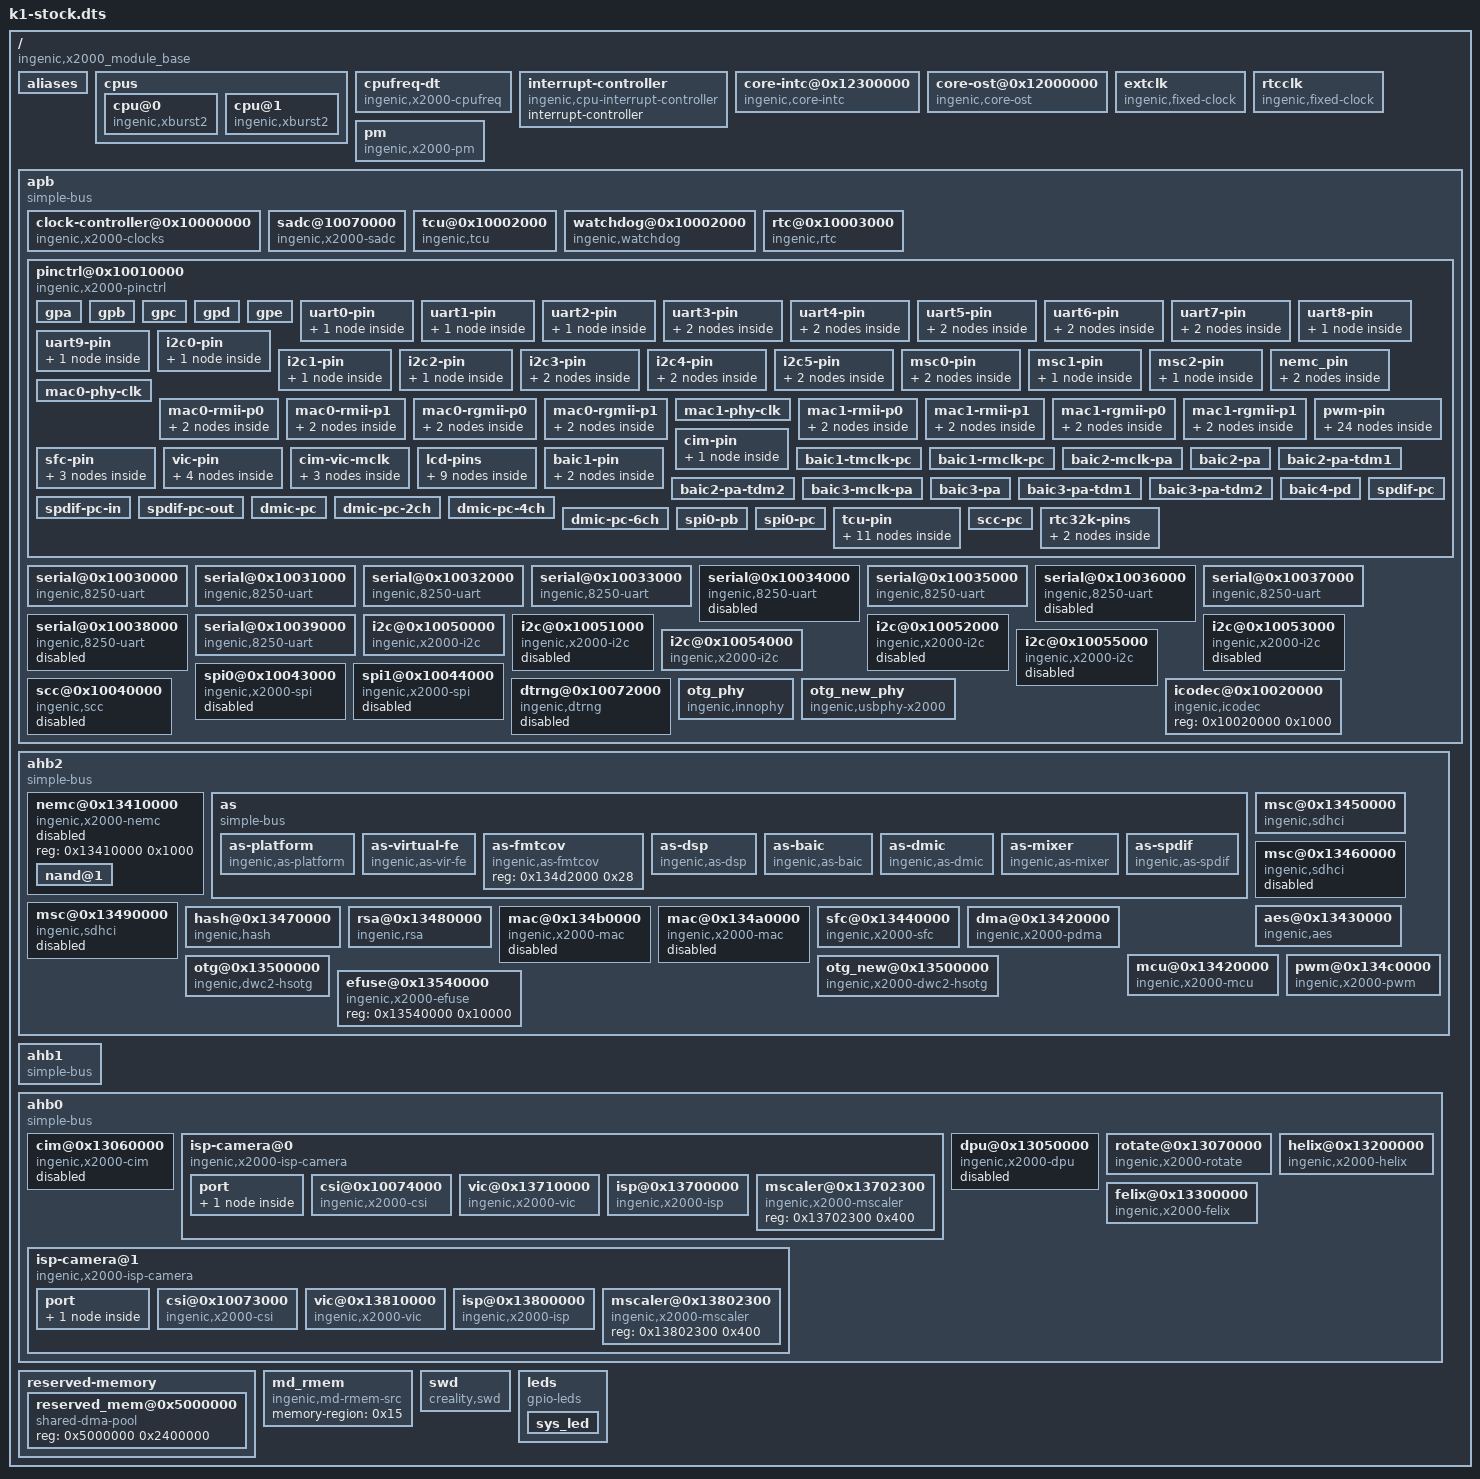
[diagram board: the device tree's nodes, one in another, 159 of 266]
/dts-v1/;

/ {
	#address-cells = <0x01>;
	#size-cells = <0x01>;
	compatible = "ingenic,x2000_module_base", "ingenic,x2000";

	aliases {
		i2c0 = "/apb/i2c@0x10050000";
		i2c1 = "/apb/i2c@0x10051000";
		i2c2 = "/apb/i2c@0x10052000";
		i2c3 = "/apb/i2c@0x10053000";
		i2c4 = "/apb/i2c@0x10054000";
		i2c5 = "/apb/i2c@0x10055000";
		uart0 = "/apb/serial@0x10030000";
		uart1 = "/apb/serial@0x10031000";
		uart2 = "/apb/serial@0x10032000";
		uart3 = "/apb/serial@0x10033000";
		uart4 = "/apb/serial@0x10034000";
		uart5 = "/apb/serial@0x10035000";
		uart6 = "/apb/serial@0x10036000";
		uart7 = "/apb/serial@0x10037000";
		uart8 = "/apb/serial@0x10038000";
		uart9 = "/apb/serial@0x10039000";
		mmc0 = "/ahb2/msc@0x13450000";
		mmc1 = "/ahb2/msc@0x13460000";
		mmc2 = "/ahb2/msc@0x13490000";
		mac0 = "/ahb2/mac@0x134b0000";
		mac1 = "/ahb2/mac@0x134a0000";
		spi0 = "/apb/spi0@0x10043000";
		spi1 = "/apb/spi1@0x10044000";
		pwm = "/ahb2/pwm@0x134c0000";
	};

	cpus {
		#address-cells = <0x01>;
		#size-cells = <0x00>;

		cpu@0 {
			device_type = "cpu";
			compatible = "ingenic,xburst2";
			reg = <0x00>;
			clock-frequency = <0x2faf0800>;
		};

		cpu@1 {
			device_type = "cpu";
			compatible = "ingenic,xburst2";
			reg = <0x01>;
			clock-frequency = <0x2faf0800>;
		};
	};

	cpufreq-dt {
		compatible = "ingenic,x2000-cpufreq";
		status = "okay";
		operating-points = <0x124f80 0xdbba0 0xb71b0 0xdbba0 0x927c0 0xdbba0 0x7a120 0xdbba0 0x61a80 0xdbba0 0x5b8d8 0xdbba0 0x493e0 0xdbba0 0x30d40 0xdbba0>;
	};

	interrupt-controller {
		#address-cells = <0x00>;
		#interrupt-cells = <0x01>;
		interrupt-controller;
		compatible = "ingenic,cpu-interrupt-controller";
		linux,phandle = <0x01>;
		phandle = <0x01>;
	};

	core-intc@0x12300000 {
		compatible = "ingenic,core-intc";
		reg = <0x12300000 0x1000 0x10001000 0x1000>;
		interrupt-controller;
		#interrupt-cells = <0x01>;
		cpu-intc-map = <0x00 0x00 0x01 0x100 0x02 0x200 0x03 0x300>;
		interrupt-parent = <0x01>;
		interrupts = <0x02>;
		interrupt-names = "intc";
		linux,phandle = <0x04>;
		phandle = <0x04>;
	};

	core-ost@0x12000000 {
		compatible = "ingenic,core-ost";
		reg = <0x12000000 0x10000 0x12100000 0x10000>;
		interrupt-parent = <0x01>;
		interrupt-names = "sys_ost";
		interrupts = <0x04>;
		cpu-ost-map = <0x00 0x00 0x01 0x100>;
	};

	extclk {
		compatible = "ingenic,fixed-clock";
		clock-output-names = "ext";
		#clock-cells = <0x00>;
		clock-frequency = <0x16e3600>;
		linux,phandle = <0x02>;
		phandle = <0x02>;
	};

	rtcclk {
		compatible = "ingenic,fixed-clock";
		clock-output-names = "rtc_ext";
		#clock-cells = <0x00>;
		clock-frequency = <0x8000>;
		linux,phandle = <0x03>;
		phandle = <0x03>;
	};

	pm {
		compatible = "ingenic,x2000-pm";
		status = "okay";
	};

	apb {
		compatible = "simple-bus";
		#address-cells = <0x01>;
		#size-cells = <0x01>;
		ranges;

		clock-controller@0x10000000 {
			compatible = "ingenic,x2000-clocks";
			reg = <0x10000000 0x100>;
			clocks = <0x02 0x03>;
			clock-names = "ext", "rtc_ext";
			#clock-cells = <0x01>;
			little-endian;
			linux,phandle = <0x05>;
			phandle = <0x05>;
		};

		sadc@10070000 {
			compatible = "ingenic,x2000-sadc";
			reg = <0x10070000 0x32>;
			interrupt-parent = <0x04>;
			interrupts = <0x0b>;
			interrupt-controller;
			status = "ok";
		};

		tcu@0x10002000 {
			compatible = "ingenic,tcu";
			reg = <0x10002000 0x1000>;
			interrupt-parent = <0x04>;
			interrupt-names = "default";
			interrupts = <0x1b>;
			clocks = <0x05 0x49>;
			clock-names = "gate_tcu";
			status = "ok";
		};

		watchdog@0x10002000 {
			compatible = "ingenic,watchdog";
			reg = <0x10002000 0x40>;
			interrupt-parent = <0x04>;
			interrupts = <0x1b>;
			status = "ok";
		};

		rtc@0x10003000 {
			compatible = "ingenic,rtc";
			reg = <0x10003000 0x4c>;
			interrupt-parent = <0x04>;
			interrupts = <0x20>;
			system-power-controller;
			power-on-press-ms = <0x3e8>;
			status = "ok";
		};

		pinctrl@0x10010000 {
			compatible = "ingenic,x2000-pinctrl";
			reg = <0x10010000 0x1000>;
			ingenic,num-chips = <0x05>;
			ingenic,regs-offset = <0x100>;
			ingenic,gpa_voltage = <0x02>;
			ingenic,gpe_msc_voltage = <0x01>;

			gpa {
				gpio-controller;
				#gpio-cells = <0x03>;
				#ingenic,pincfg-cells = <0x03>;
				#ingenic,pinmux-cells = <0x02>;
				interrupts = <0x11>;
				interrupt-parent = <0x04>;
				interrupt-controller;
				#interrupt-cells = <0x03>;
				ingenic,num-gpios = <0x20>;
				linux,phandle = <0x08>;
				phandle = <0x08>;
			};

			gpb {
				gpio-controller;
				#gpio-cells = <0x03>;
				#ingenic,pincfg-cells = <0x03>;
				#ingenic,pinmux-cells = <0x02>;
				interrupts = <0x10>;
				interrupt-parent = <0x04>;
				interrupt-controller;
				#interrupt-cells = <0x03>;
				ingenic,num-gpios = <0x20>;
				linux,phandle = <0x09>;
				phandle = <0x09>;
			};

			gpc {
				gpio-controller;
				#gpio-cells = <0x03>;
				#ingenic,pincfg-cells = <0x03>;
				#ingenic,pinmux-cells = <0x02>;
				interrupts = <0x0f>;
				interrupt-parent = <0x04>;
				interrupt-controller;
				#interrupt-cells = <0x03>;
				ingenic,num-gpios = <0x20>;
				linux,phandle = <0x07>;
				phandle = <0x07>;
			};

			gpd {
				gpio-controller;
				#gpio-cells = <0x03>;
				#ingenic,pincfg-cells = <0x03>;
				#ingenic,pinmux-cells = <0x02>;
				interrupts = <0x0e>;
				interrupt-parent = <0x04>;
				interrupt-controller;
				#interrupt-cells = <0x03>;
				ingenic,num-gpios = <0x20>;
				linux,phandle = <0x06>;
				phandle = <0x06>;
			};

			gpe {
				gpio-controller;
				#gpio-cells = <0x03>;
				#ingenic,pincfg-cells = <0x03>;
				#ingenic,pinmux-cells = <0x02>;
				interrupts = <0x0d>;
				interrupt-parent = <0x04>;
				interrupt-controller;
				#interrupt-cells = <0x03>;
				ingenic,num-gpios = <0x20>;
				linux,phandle = <0x0a>;
				phandle = <0x0a>;
			};

			uart0-pin {

				uart0-pd {
					ingenic,pinmux = <0x06 0x17 0x1a>;
					ingenic,pinmux-funcsel = <0x02>;
				};
			};

			uart1-pin {

				uart1-pc {
					ingenic,pinmux = <0x07 0x17 0x18>;
					ingenic,pinmux-funcsel = <0x01>;
					linux,phandle = <0x0b>;
					phandle = <0x0b>;
				};
			};

			uart2-pin {

				uart2-pd {
					ingenic,pinmux = <0x06 0x1e 0x1f>;
					ingenic,pinmux-funcsel = <0x00>;
					linux,phandle = <0x0c>;
					phandle = <0x0c>;
				};
			};

			uart3-pin {

				uart3-pc {
					ingenic,pinmux = <0x07 0x19 0x1a>;
					ingenic,pinmux-funcsel = <0x00>;
				};

				uart3-pd {
					ingenic,pinmux = <0x06 0x00 0x03>;
					ingenic,pinmux-funcsel = <0x01>;
					linux,phandle = <0x0d>;
					phandle = <0x0d>;
				};
			};

			uart4-pin {

				uart4-pa {
					ingenic,pinmux = <0x08 0x00 0x03>;
					ingenic,pinmux-funcsel = <0x01>;
				};

				uart4-pc {
					ingenic,pinmux = <0x07 0x09 0x0c>;
					ingenic,pinmux-funcsel = <0x03>;
				};
			};

			uart5-pin {

				uart5-pa {
					ingenic,pinmux = <0x08 0x04 0x05>;
					ingenic,pinmux-funcsel = <0x01>;
					linux,phandle = <0x0e>;
					phandle = <0x0e>;
				};

				uart5-pc {
					ingenic,pinmux = <0x07 0x05 0x06>;
					ingenic,pinmux-funcsel = <0x03>;
				};
			};

			uart6-pin {

				uart6-pa {
					ingenic,pinmux = <0x08 0x06 0x07>;
					ingenic,pinmux-funcsel = <0x01>;
				};

				uart6-pc {
					ingenic,pinmux = <0x07 0x07 0x08>;
					ingenic,pinmux-funcsel = <0x03>;
				};
			};

			uart7-pin {

				uart7-pa {
					ingenic,pinmux = <0x08 0x08 0x09>;
					ingenic,pinmux-funcsel = <0x01>;
					linux,phandle = <0x0f>;
					phandle = <0x0f>;
				};

				uart7-pc {
					ingenic,pinmux = <0x07 0x01 0x02>;
					ingenic,pinmux-funcsel = <0x03>;
				};
			};

			uart8-pin {

				uart8-pb {
					ingenic,pinmux = <0x09 0x1c 0x1d>;
					ingenic,pinmux-funcsel = <0x03>;
				};
			};

			uart9-pin {

				uart9-pb {
					ingenic,pinmux = <0x09 0x1e 0x1f>;
					ingenic,pinmux-funcsel = <0x03>;
					linux,phandle = <0x10>;
					phandle = <0x10>;
				};
			};

			i2c0-pin {

				i2c0-pc {
					ingenic,pinmux = <0x07 0x0d 0x0e>;
					ingenic,pinmux-funcsel = <0x03>;
				};
			};

			i2c1-pin {

				i2c1-pc {
					ingenic,pinmux = <0x07 0x17 0x18>;
					ingenic,pinmux-funcsel = <0x02>;
				};
			};

			i2c2-pin {

				i2c2-pb {
					ingenic,pinmux = <0x09 0x16 0x17>;
					ingenic,pinmux-funcsel = <0x02>;
				};
			};

			i2c3-pin {

				i2c3-pd {
					ingenic,pinmux = <0x06 0x1e 0x1f>;
					ingenic,pinmux-funcsel = <0x01>;
				};

				i2c3-pa {
					ingenic,pinmux = <0x08 0x10 0x11>;
					ingenic,pinmux-funcsel = <0x00>;
				};
			};

			i2c4-pin {

				i2c4-pc {
					ingenic,pinmux = <0x07 0x19 0x1a>;
					ingenic,pinmux-funcsel = <0x01>;
				};

				i2c4-pd {
					ingenic,pinmux = <0x06 0x00 0x01>;
					ingenic,pinmux-funcsel = <0x02>;
				};
			};

			i2c5-pin {

				i2c5-pc {
					ingenic,pinmux = <0x07 0x1b 0x1c>;
					ingenic,pinmux-funcsel = <0x01>;
				};

				i2c5-pd {
					ingenic,pinmux = <0x06 0x04 0x05>;
					ingenic,pinmux-funcsel = <0x01>;
				};
			};

			msc0-pin {

				msc0-4bit {
					ingenic,pinmux = <0x06 0x11 0x16>;
					ingenic,pinmux-funcsel = <0x00>;
				};

				msc0-8bit {
					ingenic,pinmux = <0x06 0x11 0x1a>;
					ingenic,pinmux-funcsel = <0x00>;
					linux,phandle = <0x12>;
					phandle = <0x12>;
				};
			};

			msc1-pin {

				msc1-4bit {
					ingenic,pinmux = <0x06 0x08 0x0d>;
					ingenic,pinmux-funcsel = <0x00>;
				};
			};

			msc2-pin {

				msc2-4bit {
					ingenic,pinmux = <0x0a 0x00 0x05>;
					ingenic,pinmux-funcsel = <0x00>;
				};
			};

			nemc_pin {

				nemc_pb {
					ingenic,pinmux = <0x09 0x00 0x1f>;
					ingenic,pinmux-funcsel = <0x00>;
				};

				nemc_pc {
					ingenic,pinmux = <0x07 0x17 0x18>;
					ingenic,pinmux-funcsel = <0x03>;
				};
			};

			mac0-phy-clk {
				ingenic,pinmux = <0x07 0x01 0x01>;
				ingenic,pinmux-funcsel = <0x01>;
				ingenic,pincfg = <0x07 0x01 0x01 0x40009>;
			};

			mac0-rmii-p0 {

				mac0-rmii-normal {
					ingenic,pinmux = <0x07 0x06 0x07 0x07 0x0b 0x0b 0x07 0x0f 0x0f>;
					ingenic,pinmux-funcsel = <0x01>;
					ingenic,pincfg = <0x07 0x06 0x07 0x1000b 0x07 0x0b 0x0b 0x1000b 0x07 0x0f 0x0f 0x1000b>;
				};

				mac0-rmii-p0-rst {
					ingenic,pinmux = <0x07 0x06 0x07 0x07 0x0b 0x0b 0x07 0x0f 0x0f>;
					ingenic,pinmux-funcsel = <0x06>;
					ingenic,pincfg = <0x07 0x06 0x07 0x10002 0x07 0x0b 0x0b 0x10002 0x07 0x0f 0x0f 0x10002>;
				};
			};

			mac0-rmii-p1 {

				mac0-rmii-p1-normal {
					ingenic,pinmux = <0x07 0x02 0x03 0x07 0x0a 0x0a 0x07 0x0c 0x0d>;
					ingenic,pinmux-funcsel = <0x01>;
					ingenic,pincfg = <0x07 0x02 0x03 0x40009 0x07 0x0a 0x0a 0x40009 0x07 0x0c 0x0d 0x40009>;
				};

				mac0-rmii-p1-nomdio {
					ingenic,pinmux = <0x07 0x02 0x03 0x07 0x0a 0x0a>;
					ingenic,pinmux-funcsel = <0x01>;
					ingenic,pincfg = <0x07 0x02 0x03 0x40009 0x07 0x0a 0x0a 0x40009>;
				};
			};

			mac0-rgmii-p0 {

				mac0-rgmii-normal {
					ingenic,pinmux = <0x07 0x06 0x09 0x07 0x0b 0x0b 0x07 0x0f 0x0f>;
					ingenic,pinmux-funcsel = <0x01>;
					ingenic,pincfg = <0x07 0x06 0x09 0x1000b 0x07 0x0b 0x0b 0x1000b 0x07 0x0f 0x0f 0x1000b>;
				};

				mac0-rgmii-p0-rst {
					ingenic,pinmux = <0x07 0x06 0x09 0x07 0x0b 0x0b 0x07 0x0f 0x0f>;
					ingenic,pinmux-funcsel = <0x06>;
					ingenic,pincfg = <0x07 0x06 0x09 0x10002 0x07 0x0b 0x0b 0x10002 0x07 0x0f 0x0f 0x10002>;
				};
			};

			mac0-rgmii-p1 {

				mac0-rgmii-p1-normal {
					ingenic,pinmux = <0x07 0x02 0x05 0x07 0x0a 0x0a 0x07 0x0c 0x0e>;
					ingenic,pinmux-funcsel = <0x01>;
					ingenic,pincfg = <0x07 0x02 0x05 0x40009 0x07 0x0a 0x0a 0x40009 0x07 0x0c 0x0e 0x40009>;
				};

				mac0-rgmii-p1-nomdio {
					ingenic,pinmux = <0x07 0x02 0x05 0x07 0x0a 0x0a 0x07 0x0e 0x0e>;
					ingenic,pinmux-funcsel = <0x01>;
					ingenic,pincfg = <0x07 0x02 0x05 0x40009 0x07 0x0a 0x0a 0x40009 0x07 0x0e 0x0e 0x40009>;
				};
			};

			mac1-phy-clk {
				ingenic,pinmux = <0x09 0x17 0x17>;
				ingenic,pinmux-funcsel = <0x03>;
				ingenic,pincfg = <0x07 0x17 0x17 0x40009>;
			};

			mac1-rmii-p0 {

				mac1-rmii-normal {
					ingenic,pinmux = <0x09 0x0c 0x0d 0x09 0x12 0x12 0x09 0x16 0x16>;
					ingenic,pinmux-funcsel = <0x03>;
					ingenic,pincfg = <0x09 0x0c 0x0d 0x1000b 0x09 0x12 0x12 0x1000b 0x09 0x16 0x16 0x1000b>;
				};

				mac1-rmii-p0-rst {
					ingenic,pinmux = <0x09 0x0c 0x0d 0x09 0x12 0x12 0x09 0x16 0x16>;
					ingenic,pinmux-funcsel = <0x06>;
					ingenic,pincfg = <0x09 0x0c 0x0d 0x10002 0x09 0x12 0x12 0x10002 0x09 0x16 0x16 0x10002>;
				};
			};

			mac1-rmii-p1 {

				mac1-rmii-p1-normal {
					ingenic,pinmux = <0x09 0x08 0x09 0x09 0x11 0x11 0x09 0x13 0x14>;
					ingenic,pinmux-funcsel = <0x03>;
					ingenic,pincfg = <0x09 0x08 0x09 0x40009 0x09 0x11 0x11 0x40009 0x09 0x13 0x14 0x40009>;
				};

				mac1-rmii-p1-nomdio {
					ingenic,pinmux = <0x09 0x08 0x09 0x09 0x11 0x11>;
					ingenic,pinmux-funcsel = <0x03>;
					ingenic,pincfg = <0x09 0x08 0x09 0x40009 0x09 0x11 0x11 0x40009>;
				};
			};

			mac1-rgmii-p0 {

				mac1-rgmii-normal {
					ingenic,pinmux = <0x09 0x0c 0x0f 0x09 0x12 0x12 0x09 0x16 0x16>;
					ingenic,pinmux-funcsel = <0x03>;
					ingenic,pincfg = <0x09 0x0c 0x0f 0x1000b 0x09 0x12 0x12 0x1000b 0x09 0x16 0x16 0x1000b>;
				};

				mac1-rgmii-p0-rst {
					ingenic,pinmux = <0x09 0x0c 0x0f 0x09 0x12 0x12 0x09 0x16 0x16>;
					ingenic,pinmux-funcsel = <0x06>;
					ingenic,pincfg = <0x09 0x0c 0x0f 0x10002 0x09 0x12 0x12 0x10002 0x09 0x16 0x16 0x10002>;
				};
			};

			mac1-rgmii-p1 {

				mac1-rgmii-p1-normal {
					ingenic,pinmux = <0x09 0x08 0x0b 0x09 0x11 0x11 0x09 0x13 0x15>;
					ingenic,pinmux-funcsel = <0x03>;
					ingenic,pincfg = <0x09 0x08 0x0b 0x40009 0x09 0x11 0x11 0x40009 0x09 0x13 0x15 0x40009>;
				};

				mac1-rgmii-p1-nomdio {
					ingenic,pinmux = <0x09 0x08 0x0b 0x09 0x11 0x11 0x09 0x15 0x15>;
					ingenic,pinmux-funcsel = <0x03>;
					ingenic,pincfg = <0x09 0x08 0x0b 0x40009 0x09 0x11 0x11 0x40009 0x09 0x15 0x15 0x40009>;
				};
			};

			pwm-pin {

				pwm0_pc {
					ingenic,pinmux = <0x07 0x00 0x00>;
					ingenic,pinmux-funcsel = <0x00>;
				};

				pwm1_pc {
					ingenic,pinmux = <0x07 0x01 0x01>;
					ingenic,pinmux-funcsel = <0x00>;
				};

				pwm2_pc {
					ingenic,pinmux = <0x07 0x02 0x02>;
					ingenic,pinmux-funcsel = <0x00>;
				};

				pwm3_pc {
					ingenic,pinmux = <0x07 0x03 0x03>;
					ingenic,pinmux-funcsel = <0x00>;
				};

				pwm4_pc {
					ingenic,pinmux = <0x07 0x04 0x04>;
					ingenic,pinmux-funcsel = <0x00>;
				};

				pwm5_pc {
					ingenic,pinmux = <0x07 0x05 0x05>;
					ingenic,pinmux-funcsel = <0x00>;
				};

				pwm6_pc {
					ingenic,pinmux = <0x07 0x06 0x06>;
					ingenic,pinmux-funcsel = <0x00>;
				};

				pwm7_pc {
					ingenic,pinmux = <0x07 0x07 0x07>;
					ingenic,pinmux-funcsel = <0x00>;
				};

				pwm8_pc {
					ingenic,pinmux = <0x07 0x08 0x08>;
					ingenic,pinmux-funcsel = <0x00>;
				};

				pwm9_pc {
					ingenic,pinmux = <0x07 0x09 0x09>;
					ingenic,pinmux-funcsel = <0x00>;
				};

				pwm10_pc {
					ingenic,pinmux = <0x07 0x0a 0x0a>;
					ingenic,pinmux-funcsel = <0x00>;
				};

				pwm11_pc {
					ingenic,pinmux = <0x07 0x0b 0x0b>;
					ingenic,pinmux-funcsel = <0x00>;
				};

				pwm12_pc {
					ingenic,pinmux = <0x07 0x0c 0x0c>;
					ingenic,pinmux-funcsel = <0x00>;
				};

				pwm13_pc {
					ingenic,pinmux = <0x07 0x0d 0x0d>;
					ingenic,pinmux-funcsel = <0x00>;
				};

				pwm14_pc {
					ingenic,pinmux = <0x07 0x0e 0x0e>;
					ingenic,pinmux-funcsel = <0x00>;
				};

				pwm15_pc {
					ingenic,pinmux = <0x07 0x0f 0x0f>;
					ingenic,pinmux-funcsel = <0x00>;
				};

				pwm0_pd {
					ingenic,pinmux = <0x06 0x1e 0x1e>;
					ingenic,pinmux-funcsel = <0x02>;
				};

				pwm1_pd {
					ingenic,pinmux = <0x06 0x1f 0x1f>;
					ingenic,pinmux-funcsel = <0x02>;
				};

				pwm2_pe {
					ingenic,pinmux = <0x0a 0x00 0x00>;
					ingenic,pinmux-funcsel = <0x01>;
				};

				pwm3_pe {
					ingenic,pinmux = <0x0a 0x01 0x01>;
					ingenic,pinmux-funcsel = <0x01>;
				};

				pwm4_pe {
					ingenic,pinmux = <0x0a 0x02 0x02>;
					ingenic,pinmux-funcsel = <0x01>;
				};

				pwm5_pe {
					ingenic,pinmux = <0x0a 0x03 0x03>;
					ingenic,pinmux-funcsel = <0x01>;
				};

				pwm6_pe {
					ingenic,pinmux = <0x0a 0x04 0x04>;
					ingenic,pinmux-funcsel = <0x01>;
				};

				pwm7_pe {
					ingenic,pinmux = <0x0a 0x05 0x05>;
					ingenic,pinmux-funcsel = <0x01>;
				};
			};

			sfc-pin {

				sfc-pd_8bit {
					ingenic,pinmux = <0x06 0x11 0x1a>;
					ingenic,pinmux-funcsel = <0x01>;
				};

				sfc-pd_4bit {
					ingenic,pinmux = <0x06 0x11 0x16>;
					ingenic,pinmux-funcsel = <0x01>;
				};

				sfc-pe {
					ingenic,pinmux = <0x0a 0x10 0x15>;
					ingenic,pinmux-funcsel = <0x00>;
				};
			};

			cim-pin {

				cim-pa {
					ingenic,pinmux = <0x08 0x00 0x07 0x08 0x0c 0x0f>;
					ingenic,pinmux-funcsel = <0x00>;
				};
			};

			vic-pin {

				vic-pa-low-8bit {
					ingenic,pinmux = <0x08 0x00 0x07 0x08 0x0c 0x0e>;
					ingenic,pinmux-funcsel = <0x00>;
				};

				vic-pa-low-10bit {
					ingenic,pinmux = <0x08 0x00 0x09 0x08 0x0c 0x0e>;
					ingenic,pinmux-funcsel = <0x00>;
				};

				vic-pa-high-10bit {
					ingenic,pinmux = <0x08 0x02 0x0e>;
					ingenic,pinmux-funcsel = <0x00>;
				};

				vic-pa-12bit {
					ingenic,pinmux = <0x08 0x00 0x0e>;
					ingenic,pinmux-funcsel = <0x00>;
				};
			};

			cim-vic-mclk {

				cim-vic-mclk-pe-24M {
					ingenic,pinmux = <0x0a 0x18 0x18>;
					ingenic,pinmux-funcsel = <0x00>;
				};

				cim-vic-mclk-pe {
					ingenic,pinmux = <0x0a 0x18 0x18>;
					ingenic,pinmux-funcsel = <0x01>;
				};

				cim-vic-mclk-pc {
					ingenic,pinmux = <0x07 0x0f 0x0f>;
					ingenic,pinmux-funcsel = <0x02>;
				};
			};

			lcd-pins {

				tft-lcd-pb-rgb888 {
					ingenic,pinmux = <0x09 0x00 0x1b>;
					ingenic,pinmux-funcsel = <0x01>;
				};

				tft-lcd-pb-rgb888_to_18bit {
					ingenic,pinmux = <0x09 0x02 0x07 0x09 0x0a 0x0f 0x09 0x12 0x1b>;
					ingenic,pinmux-funcsel = <0x01>;
				};

				tft-lcd-pb-rgb565 {
					ingenic,pinmux = <0x09 0x00 0x0f 0x09 0x18 0x1b>;
					ingenic,pinmux-funcsel = <0x01>;
				};

				tft-lcd-pb-rgb666 {
					ingenic,pinmux = <0x09 0x00 0x11 0x09 0x18 0x1b>;
					ingenic,pinmux-funcsel = <0x01>;
				};

				smart-lcd-pb-16bit {
					ingenic,pinmux = <0x09 0x00 0x0f 0x09 0x19 0x1b>;
					ingenic,pinmux-funcsel = <0x02>;
				};

				smart-lcd-pb-9bit {
					ingenic,pinmux = <0x09 0x00 0x08 0x09 0x19 0x1b>;
					ingenic,pinmux-funcsel = <0x02>;
				};

				smart-lcd-pb-8bit {
					ingenic,pinmux = <0x09 0x00 0x07 0x09 0x19 0x1b>;
					ingenic,pinmux-funcsel = <0x02>;
				};

				smart-lcd-pb-spi {
					ingenic,pinmux = <0x09 0x00 0x00 0x09 0x19 0x1a>;
					ingenic,pinmux-funcsel = <0x02>;
				};

				smart-lcd-pb-te {
					ingenic,pinmux = <0x09 0x1b 0x1b>;
					ingenic,pinmux-funcsel = <0x02>;
				};
			};

			baic1-tmclk-pc {
				ingenic,pinmux = <0x07 0x08 0x08>;
				ingenic,pinmux-funcsel = <0x02>;
			};

			baic1-rmclk-pc {
				ingenic,pinmux = <0x07 0x01 0x01>;
				ingenic,pinmux-funcsel = <0x02>;
			};

			baic1-pin {

				baic1-pin-pc {
					ingenic,pinmux = <0x07 0x02 0x07>;
					ingenic,pinmux-funcsel = <0x02>;
				};

				baic1-cpin-pc {
					ingenic,pinmux = <0x07 0x04 0x07>;
					ingenic,pinmux-funcsel = <0x02>;
				};
			};

			baic2-mclk-pa {
				ingenic,pinmux = <0x08 0x07 0x07>;
				ingenic,pinmux-funcsel = <0x02>;
			};

			baic2-pa {
				ingenic,pinmux = <0x08 0x09 0x0d 0x08 0x11 0x11>;
				ingenic,pinmux-funcsel = <0x02>;
			};

			baic2-pa-tdm1 {
				ingenic,pinmux = <0x08 0x09 0x0a 0x08 0x11 0x11>;
				ingenic,pinmux-funcsel = <0x02>;
			};

			baic2-pa-tdm2 {
				ingenic,pinmux = <0x08 0x09 0x0b 0x08 0x11 0x11>;
				ingenic,pinmux-funcsel = <0x02>;
			};

			baic3-mclk-pa {
				ingenic,pinmux = <0x08 0x00 0x00>;
				ingenic,pinmux-funcsel = <0x02>;
			};

			baic3-pa {
				ingenic,pinmux = <0x08 0x02 0x06 0x08 0x10 0x10>;
				ingenic,pinmux-funcsel = <0x02>;
			};

			baic3-pa-tdm1 {
				ingenic,pinmux = <0x08 0x02 0x03 0x08 0x10 0x10>;
				ingenic,pinmux-funcsel = <0x02>;
			};

			baic3-pa-tdm2 {
				ingenic,pinmux = <0x08 0x02 0x04 0x08 0x10 0x10>;
				ingenic,pinmux-funcsel = <0x02>;
			};

			baic4-pd {
				ingenic,pinmux = <0x06 0x02 0x05>;
				ingenic,pinmux-funcsel = <0x02>;
				ingenic,pincfg = <0x06 0x04 0x04 0x10002>;
			};

			spdif-pc {
				ingenic,pinmux = <0x07 0x0d 0x0e>;
				ingenic,pinmux-funcsel = <0x02>;
				ingenic,pincfg = <0x07 0x0e 0x0e 0x70009>;
			};

			spdif-pc-in {
				ingenic,pinmux = <0x07 0x0d 0x0d>;
				ingenic,pinmux-funcsel = <0x02>;
			};

			spdif-pc-out {
				ingenic,pinmux = <0x07 0x0e 0x0e>;
				ingenic,pinmux-funcsel = <0x02>;
				ingenic,pincfg = <0x07 0x0e 0x0e 0x70009>;
			};

			dmic-pc {
				ingenic,pinmux = <0x07 0x14 0x18>;
				ingenic,pinmux-funcsel = <0x00>;
			};

			dmic-pc-2ch {
				ingenic,pinmux = <0x07 0x14 0x15>;
				ingenic,pinmux-funcsel = <0x00>;
			};

			dmic-pc-4ch {
				ingenic,pinmux = <0x07 0x14 0x16>;
				ingenic,pinmux-funcsel = <0x00>;
			};

			dmic-pc-6ch {
				ingenic,pinmux = <0x07 0x14 0x17>;
				ingenic,pinmux-funcsel = <0x00>;
			};

			spi0-pb {
				ingenic,pinmux = <0x09 0x1c 0x1f>;
				ingenic,pinmux-funcsel = <0x01>;
			};

			spi0-pc {
				ingenic,pinmux = <0x07 0x09 0x0c>;
				ingenic,pinmux-funcsel = <0x02>;
			};

			tcu-pin {

				tcu0_pc {
					ingenic,pinmux = <0x07 0x00 0x01>;
					ingenic,pinmux-funcsel = <0x00>;
				};

				tcu1_pc {
					ingenic,pinmux = <0x07 0x02 0x03>;
					ingenic,pinmux-funcsel = <0x00>;
				};

				tcu2_pc {
					ingenic,pinmux = <0x07 0x04 0x05>;
					ingenic,pinmux-funcsel = <0x00>;
				};

				tcu3_pc {
					ingenic,pinmux = <0x07 0x06 0x07>;
					ingenic,pinmux-funcsel = <0x00>;
				};

				tcu4_pc {
					ingenic,pinmux = <0x07 0x08 0x09>;
					ingenic,pinmux-funcsel = <0x00>;
				};

				tcu5_pc {
					ingenic,pinmux = <0x07 0x0a 0x0b>;
					ingenic,pinmux-funcsel = <0x00>;
				};

				tcu5_pe {
					ingenic,pinmux = <0x0a 0x10 0x11>;
					ingenic,pinmux-funcsel = <0x01>;
				};

				tcu6_pc {
					ingenic,pinmux = <0x07 0x0c 0x0d>;
					ingenic,pinmux-funcsel = <0x00>;
				};

				tcu6_pe {
					ingenic,pinmux = <0x0a 0x12 0x13>;
					ingenic,pinmux-funcsel = <0x01>;
				};

				tcu7_pc {
					ingenic,pinmux = <0x07 0x0e 0x0f>;
					ingenic,pinmux-funcsel = <0x00>;
				};

				tcu7_pe {
					ingenic,pinmux = <0x0a 0x14 0x15>;
					ingenic,pinmux-funcsel = <0x01>;
				};
			};

			scc-pc {
				ingenic,pinmux = <0x07 0x03 0x04>;
				ingenic,pinmux-funcsel = <0x03>;
			};

			rtc32k-pins {

				rtc32k-enable {
					ingenic,pinmux = <0x0a 0x17 0x17>;
					ingenic,pinmux-funcsel = <0x00>;
				};

				rtc32k-disable {
					ingenic,pinmux = <0x0a 0x17 0x17>;
					ingenic,pinmux-funcsel = <0x0c>;
				};
			};
		};

		serial@0x10030000 {
			compatible = "ingenic,8250-uart";
			reg = <0x10030000 0x100>;
			reg-shift = <0x02>;
			interrupt-parent = <0x04>;
			interrupts = <0x2f>;
			clocks = <0x05 0x4d>;
			clock-names = "uart0";
		};

		serial@0x10031000 {
			compatible = "ingenic,8250-uart";
			reg = <0x10031000 0x100>;
			reg-shift = <0x02>;
			interrupt-parent = <0x04>;
			interrupts = <0x2e>;
			clocks = <0x05 0x4c>;
			clock-names = "uart1";
			status = "okay";
			pinctrl-names = "default";
			pinctrl-0 = <0x0b>;
		};

		serial@0x10032000 {
			compatible = "ingenic,8250-uart";
			reg = <0x10032000 0x100>;
			reg-shift = <0x02>;
			interrupt-parent = <0x04>;
			interrupts = <0x2d>;
			clocks = <0x05 0x4b>;
			clock-names = "uart2";
			status = "okay";
			pinctrl-names = "default";
			pinctrl-0 = <0x0c>;
		};

		serial@0x10033000 {
			compatible = "ingenic,8250-uart";
			reg = <0x10033000 0x100>;
			reg-shift = <0x02>;
			interrupt-parent = <0x04>;
			interrupts = <0x2c>;
			clocks = <0x05 0x69>;
			clock-names = "uart3";
			status = "okay";
			pinctrl-names = "default";
			pinctrl-0 = <0x0d>;
		};

		serial@0x10034000 {
			compatible = "ingenic,8250-uart";
			reg = <0x10034000 0x100>;
			reg-shift = <0x02>;
			interrupt-parent = <0x04>;
			interrupts = <0x2b>;
			clocks = <0x05 0x68>;
			clock-names = "uart4";
			status = "disabled";
		};

		serial@0x10035000 {
			compatible = "ingenic,8250-uart";
			reg = <0x10035000 0x100>;
			reg-shift = <0x02>;
			interrupt-parent = <0x04>;
			interrupts = <0x2a>;
			clocks = <0x05 0x67>;
			clock-names = "uart5";
			status = "okay";
			pinctrl-names = "default";
			pinctrl-0 = <0x0e>;
		};

		serial@0x10036000 {
			compatible = "ingenic,8250-uart";
			reg = <0x10036000 0x100>;
			reg-shift = <0x02>;
			interrupt-parent = <0x04>;
			interrupts = <0x29>;
			clocks = <0x05 0x66>;
			clock-names = "uart6";
			status = "disabled";
		};

		serial@0x10037000 {
			compatible = "ingenic,8250-uart";
			reg = <0x10037000 0x100>;
			reg-shift = <0x02>;
			interrupt-parent = <0x04>;
			interrupts = <0x28>;
			clocks = <0x05 0x65>;
			clock-names = "uart7";
			status = "okay";
			pinctrl-names = "default";
			pinctrl-0 = <0x0f>;
		};

		serial@0x10038000 {
			compatible = "ingenic,8250-uart";
			reg = <0x10038000 0x100>;
			reg-shift = <0x02>;
			interrupt-parent = <0x04>;
			interrupts = <0x27>;
			clocks = <0x05 0x64>;
			clock-names = "uart8";
			status = "disabled";
		};

		serial@0x10039000 {
			compatible = "ingenic,8250-uart";
			reg = <0x10039000 0x100>;
			reg-shift = <0x02>;
			interrupt-parent = <0x04>;
			interrupts = <0x26>;
			clocks = <0x05 0x63>;
			clock-names = "uart9";
			status = "okay";
			pinctrl-names = "default";
			pinctrl-0 = <0x10>;
		};

		i2c@0x10050000 {
			compatible = "ingenic,x2000-i2c";
			reg = <0x10050000 0x1000>;
			interrupt-parent = <0x04>;
			interrupts = <0x3d>;
			#address-cells = <0x01>;
			#size-cells = <0x00>;
			status = "okay";
		};

		i2c@0x10051000 {
			compatible = "ingenic,x2000-i2c";
			reg = <0x10051000 0x1000>;
			interrupt-parent = <0x04>;
			interrupts = <0x3c>;
			#address-cells = <0x01>;
			#size-cells = <0x00>;
			status = "disabled";
		};

		i2c@0x10052000 {
			compatible = "ingenic,x2000-i2c";
			reg = <0x10052000 0x1000>;
			interrupt-parent = <0x04>;
			interrupts = <0x3b>;
			#address-cells = <0x01>;
			#size-cells = <0x00>;
			status = "disabled";
		};

		i2c@0x10053000 {
			compatible = "ingenic,x2000-i2c";
			reg = <0x10053000 0x1000>;
			interrupt-parent = <0x04>;
			interrupts = <0x3a>;
			#address-cells = <0x01>;
			#size-cells = <0x00>;
			status = "disabled";
		};

		i2c@0x10054000 {
			compatible = "ingenic,x2000-i2c";
			reg = <0x10054000 0x1000>;
			interrupt-parent = <0x04>;
			interrupts = <0x39>;
			#address-cells = <0x01>;
			#size-cells = <0x00>;
			status = "okay";
		};

		i2c@0x10055000 {
			compatible = "ingenic,x2000-i2c";
			reg = <0x10055000 0x1000>;
			interrupt-parent = <0x04>;
			interrupts = <0x38>;
			#address-cells = <0x01>;
			#size-cells = <0x00>;
			status = "disabled";
		};

		spi0@0x10043000 {
			compatible = "ingenic,x2000-spi";
			reg = <0x10043000 0x1000>;
			interrupt-parent = <0x04>;
			interrupts = <0x09>;
			dmas = <0x11 0x16 0x11 0x17>;
			dma-names = "tx", "rx";
			#address-cells = <0x01>;
			#size-cells = <0x00>;
			status = "disabled";
		};

		spi1@0x10044000 {
			compatible = "ingenic,x2000-spi";
			reg = <0x10044000 0x1000>;
			interrupt-parent = <0x04>;
			interrupts = <0x08>;
			dmas = <0x11 0x18 0x11 0x19>;
			dma-names = "tx", "rx";
			#address-cells = <0x01>;
			#size-cells = <0x00>;
			status = "disabled";
		};

		scc@0x10040000 {
			compatible = "ingenic,scc";
			reg = <0x10040000 0x100>;
			interrupt-parent = <0x04>;
			interrupts = <0x23>;
			status = "disabled";
		};

		dtrng@0x10072000 {
			compatible = "ingenic,dtrng";
			reg = <0x10072000 0x100>;
			interrupt-parent = <0x04>;
			interrupts = <0x22>;
			status = "disabled";
		};

		otg_phy {
			#address-cells = <0x01>;
			#size-cells = <0x01>;
			compatible = "ingenic,innophy", "syscon";
			reg = <0x10000000 0x100 0x10078000 0x110>;
			dr_mode = "otg";
			status = "okay";
			linux,phandle = <0x13>;
			phandle = <0x13>;
		};

		otg_new_phy {
			#address-cells = <0x01>;
			#size-cells = <0x01>;
			compatible = "ingenic,usbphy-x2000";
			reg = <0x10000000 0x100 0x10078000 0x110>;
			status = "okay";
			ingenic,drvvbus-gpio = <0x08 0x0f 0x00 0x00>;
			linux,phandle = <0x14>;
			phandle = <0x14>;
		};

		icodec@0x10020000 {
			compatible = "ingenic,icodec";
			reg = <0x10020000 0x1000>;
			status = "okay";
		};
	};

	ahb2 {
		compatible = "simple-bus";
		#address-cells = <0x01>;
		#size-cells = <0x01>;
		ranges;

		nemc@0x13410000 {
			compatible = "ingenic,x2000-nemc";
			reg = <0x13410000 0x1000>;
			status = "disable";
			ranges = <0x01 0x00 0x1b000000 0x1000000 0x02 0x00 0x1a000000 0x1000000>;

			nand@1 {
				reg = <0x01 0x00 0x1000000>;
				ingenic,nemc-bus-width = <0x10>;
				ingenic,nemc-tAH = <0x0a>;
				ingenic,nemc-tAW = <0x05>;
				ingenic,nemc-tBP = <0x0a>;
				ingenic,nemc-tAS = <0x0f>;
				ingenic,nemc-tSTRV = <0x64>;
			};
		};

		as {
			compatible = "simple-bus";
			#address-cells = <0x01>;
			#size-cells = <0x01>;
			ranges;

			as-platform {
				compatible = "ingenic,as-platform";
				reg = <0x134d0000 0x114 0x134d1000 0x100>;
				reg-names = "dma", "fifo";
				ingenic,fifo-size = <0x1000>;
				interrupt-parent = <0x04>;
				interrupts = <0x00>;
				ingenic,fth_quirk;
			};

			as-virtual-fe {
				compatible = "ingenic,as-vir-fe";
				reg = <0x00 0x00>;
				ingenic,cap-dai-bm = <0x0c>;
				ingenic,num-dais = <0x04>;
			};

			as-fmtcov {
				compatible = "ingenic,as-fmtcov";
				reg = <0x134d2000 0x28>;
			};

			as-dsp {
				compatible = "ingenic,as-dsp";
				reg = <0x134d4000 0x30>;
				ingenic,li-port = <0x00 0x01 0x02 0x03 0x04 0x06 0x07 0x08 0x09 0x0a 0x0b 0x0c>;
				ingenic,lo-port = <0x00 0x01 0x02 0x03 0x04 0x05 0x06 0x07 0x08 0x09 0x0a 0x0b>;
				ingenic,cap-dai-bm = <0x3e0>;
				ingenic,num-dais = <0x0a>;
			};

			as-baic {
				compatible = "ingenic,as-baic";
				reg = <0x134d5000 0x5000>;
				ingenic,num-dais = <0x05>;
				ingenic,dai-array = <0x00 0x01 0x02 0x03 0x04>;
				ingenic,dai-mode = <0x73f 0x73f 0xfcf 0x17cf 0x73f>;
				ingenic,data-pin-num = <0x01 0x01 0x04 0x04 0x01>;
				ingenic,clk-split = <0x01 0x01 0x01 0x01 0x00>;
				ingenic,clk-rname = "div_i2s0", "div_i2s0", "div_i2s2", "no_clk", "mux_pcm";
				ingenic,clk-tname = "div_i2s1", "div_i2s1", "no_clk", "div_i2s3", "mux_pcm";
				ingenic,pcm-clk-parent = "div_i2s2";
			};

			as-dmic {
				compatible = "ingenic,as-dmic";
				reg = <0x134da000 0x10>;
				ingenic,clk-name = "mux_dmic";
				ingenic,clk-parent = "ext";
			};

			as-mixer {
				compatible = "ingenic,as-mixer";
				reg = <0x134dc000 0x08>;
				ingenic,num-mixers = <0x01>;
			};

			as-spdif {
				compatible = "ingenic,as-spdif";
				reg = <0x134db000 0x14 0x134db100 0x14>;
				reg-names = "out", "in";
				ingenic,clk-name = "mux_spdif";
				ingenic,clk-parent = "div_i2s2";
			};
		};

		msc@0x13450000 {
			compatible = "ingenic,sdhci";
			reg = <0x13450000 0x10000>;
			status = "okay";
			interrupt-parent = <0x04>;
			interrupts = <0x25>;
			pinctrl-names = "default";
			pinctrl-0 = <0x12>;
			mmc-hs200-1_8v;
			cap-mmc-highspeed;
			non-removable;
			max-frequency = <0x5f5e100>;
			bus-width = <0x08>;
			voltage-ranges = <0x708 0xce4>;
			ingenic,wp-gpios = <0x00>;
			ingneic,cd-gpios = <0x00>;
			ingenic,rst-gpios = <0x00>;
		};

		msc@0x13460000 {
			compatible = "ingenic,sdhci";
			reg = <0x13460000 0x10000>;
			status = "disabled";
			interrupt-parent = <0x04>;
			interrupts = <0x24>;
		};

		msc@0x13490000 {
			compatible = "ingenic,sdhci";
			reg = <0x13490000 0x10000>;
			status = "disabled";
			interrupt-parent = <0x04>;
			interrupts = <0x30>;
		};

		aes@0x13430000 {
			compatible = "ingenic,aes";
			reg = <0x13430000 0x10000>;
			interrupt-parent = <0x04>;
			interrupts = <0x17>;
			status = "ok";
		};

		hash@0x13470000 {
			compatible = "ingenic,hash";
			reg = <0x13470000 0x10000>;
			interrupt-parent = <0x04>;
			interrupts = <0x16>;
			status = "ok";
		};

		rsa@0x13480000 {
			compatible = "ingenic,rsa";
			reg = <0x13480000 0x10000>;
			interrupt-parent = <0x04>;
			interrupts = <0x18>;
			status = "ok";
		};

		mac@0x134b0000 {
			compatible = "ingenic,x2000-mac";
			reg = <0x134b0000 0x2000>;
			interrupt-parent = <0x04>;
			interrupts = <0x37>;
			status = "disabled";
			ingenic,rst-ms = <0x0a>;
		};

		mac@0x134a0000 {
			compatible = "ingenic,x2000-mac";
			reg = <0x134a0000 0x2000>;
			interrupt-parent = <0x04>;
			interrupts = <0x35>;
			status = "disabled";
			ingenic,rst-ms = <0x0a>;
		};

		sfc@0x13440000 {
			compatible = "ingenic,x2000-sfc";
			reg = <0x13440000 0x10000>;
			interrupt-parent = <0x04>;
			interrupts = <0x07>;
		};

		dma@0x13420000 {
			compatible = "ingenic,x2000-pdma";
			reg = <0x13420000 0x10000>;
			interrupt-parent = <0x04>;
			interrupt-names = "pdma", "pdmad";
			interrupts = <0x03 0x04>;
			#dma-channels = <0x20>;
			#dma-cells = <0x01>;
			ingenic,reserved-chs = <0x03>;
			status = "okay";
			linux,phandle = <0x11>;
			phandle = <0x11>;
		};

		mcu@0x13420000 {
			compatible = "ingenic,x2000-mcu";
			reg = <0x13420000 0x10000>;
			interrupt-parent = <0x04>;
			interrupt-names = "pdmam";
			interrupts = <0x05>;
			ingenic,tcsm_size = <0x4000>;
		};

		pwm@0x134c0000 {
			compatible = "ingenic,x2000-pwm";
			#pwm-cells = <0x02>;
			reg = <0x134c0000 0x10000>;
			interrupt-parent = <0x04>;
			interrupts = <0x06>;
		};

		otg@0x13500000 {
			compatible = "ingenic,dwc2-hsotg";
			reg = <0x13500000 0x40000>;
			interrupt-parent = <0x04>;
			interrupts = <0x01>;
			clocks = <0x05 0x58>;
			clock-names = "gate_otg";
			ingenic,usbphy = <0x13>;
			status = "okay";
			dr_mode = "otg";
		};

		otg_new@0x13500000 {
			compatible = "ingenic,x2000-dwc2-hsotg";
			reg = <0x13500000 0x40000>;
			interrupt-parent = <0x04>;
			interrupts = <0x01>;
			ingenic,usbphy = <0x14>;
			dr_mode = "otg";
			g-rx-fifo-size = <0x448>;
			g-np-tx-fifo-size = <0x200>;
			g-tx-fifo-size = <0x10 0x10 0x10 0x80 0x100 0x100 0x200 0x300>;
			status = "okay";
		};

		efuse@0x13540000 {
			compatible = "ingenic,x2000-efuse";
			reg = <0x13540000 0x10000>;
			status = "okay";
		};
	};

	ahb1 {
		compatible = "simple-bus";
		#address-cells = <0x01>;
		#size-cells = <0x01>;
		ranges;
	};

	ahb0 {
		compatible = "simple-bus";
		#address-cells = <0x01>;
		#size-cells = <0x01>;
		ranges;

		cim@0x13060000 {
			compatible = "ingenic,x2000-cim";
			reg = <0x13060000 0x10000>;
			interrupt-parent = <0x04>;
			interrupts = <0x1e>;
			clocks = <0x05 0x30 0x05 0x45 0x05 0x5e>;
			clock-names = "div_cim", "gate_cim", "gate_mipi";
			status = "disable";
		};

		isp-camera@0 {
			compatible = "ingenic,x2000-isp-camera";
			#address-cells = <0x01>;
			#size-cells = <0x01>;
			ranges;

			port {

				endpoint@0 {
				};
			};

			csi@0x10074000 {
				compatible = "ingenic,x2000-csi";
				reg = <0x10074000 0x1000>;
				interrupt-parent = <0x04>;
				interrupts = <0x0c>;
				clocks = <0x05 0x5e>;
				clock-names = "gate_csi";
			};

			vic@0x13710000 {
				compatible = "ingenic,x2000-vic";
				reg = <0x13710000 0x10000>;
				interrupt-parent = <0x04>;
				interrupts = <0x13>;
				status = "ok";
			};

			isp@0x13700000 {
				compatible = "ingenic,x2000-isp";
				reg = <0x13700000 0x2300>;
				interrupt-parent = <0x04>;
				interrupts = <0x15>;
				clocks = <0x05 0x32 0x05 0x76 0x05 0x7e>;
				clock-names = "div_isp", "gate_isp0", "power_isp0";
				status = "ok";
				ingenic,cpm_reset = <0xb00000c4>;
				ingenic,bit_sr = <0x19>;
				ingenic,bit_stp = <0x18>;
				ingenic,bit_ack = <0x17>;
			};

			mscaler@0x13702300 {
				compatible = "ingenic,x2000-mscaler";
				reg = <0x13702300 0x400>;
				status = "ok";
			};
		};

		isp-camera@1 {
			compatible = "ingenic,x2000-isp-camera";
			#address-cells = <0x01>;
			#size-cells = <0x01>;
			ranges;

			port {

				endpoint@0 {
				};
			};

			csi@0x10073000 {
				compatible = "ingenic,x2000-csi";
				reg = <0x10073000 0x1000>;
				interrupt-parent = <0x04>;
				interrupts = <0x1c>;
				clocks = <0x05 0x5e>;
				clock-names = "gate_csi";
			};

			vic@0x13810000 {
				compatible = "ingenic,x2000-vic";
				reg = <0x13810000 0x10000>;
				interrupt-parent = <0x04>;
				interrupts = <0x12>;
				status = "ok";
			};

			isp@0x13800000 {
				compatible = "ingenic,x2000-isp";
				reg = <0x13800000 0x2300>;
				interrupt-parent = <0x04>;
				interrupts = <0x14>;
				clocks = <0x05 0x32 0x05 0x75 0x05 0x7f>;
				clock-names = "div_isp", "gate_isp1", "power_isp1";
				status = "ok";
				ingenic,cpm_reset = <0xb00000c4>;
				ingenic,bit_sr = <0x16>;
				ingenic,bit_stp = <0x15>;
				ingenic,bit_ack = <0x14>;
			};

			mscaler@0x13802300 {
				compatible = "ingenic,x2000-mscaler";
				reg = <0x13802300 0x400>;
				status = "ok";
			};
		};

		dpu@0x13050000 {
			compatible = "ingenic,x2000-dpu";
			reg = <0x13050000 0x10000>;
			interrupt-parent = <0x04>;
			interrupts = <0x1f>;
			status = "disabled";
		};

		rotate@0x13070000 {
			compatible = "ingenic,x2000-rotate";
			reg = <0x13070000 0x10000>;
			interrupt-parent = <0x04>;
			interrupts = <0x1d>;
			status = "okay";
		};

		helix@0x13200000 {
			compatible = "ingenic,x2000-helix";
			reg = <0x13200000 0x100000>;
			interrupt-parent = <0x04>;
			interrupts = <0x3e>;
			status = "okay";
			memory-region = <0x15>;
		};

		felix@0x13300000 {
			compatible = "ingenic,x2000-felix";
			reg = <0x13300000 0x100000>;
			interrupt-parent = <0x04>;
			interrupts = <0x3f>;
			status = "okay";
			memory-region = <0x15>;
		};
	};

	reserved-memory {
		#address-cells = <0x01>;
		#size-cells = <0x01>;
		ranges;

		reserved_mem@0x5000000 {
			compatible = "shared-dma-pool";
			reg = <0x5000000 0x2400000>;
			linux,phandle = <0x15>;
			phandle = <0x15>;
		};
	};

	md_rmem {
		status = "okay";
		compatible = "ingenic,md-rmem-src";
		memory-region = <0x15>;
	};

	swd {
		compatible = "creality,swd";
		status = "okay";
		swdio-gpio = <0x08 0x0a 0x00 0x00>;
		swclk-gpio = <0x08 0x06 0x00 0x00>;
		nrst-gpio = <0x08 0x07 0x01 0x00>;
	};

	leds {
		compatible = "gpio-leds";
		status = "okay";

		sys_led {
			label = "sys-led";
			gpios = <0x08 0x0d 0x01 0x00>;
			linux,default-trigger = "timer";
		};
	};
};
